# SN32F400 register map
Vendor: SONiX Technology Co., Ltd.; Series: SN32F400; File version: 1.1
CPU: CM0 r0p0, little endian, no MPU, no FPU, 2 interrupt priority bits
Registers are 32-bit, read-write, reset 0x0 unless marked. A register's access mark holds for its fields unless they carry their own. Offsets are from the block's base; [hi:lo] are bit positions.

## SN_GPIO1 — General Purpose I/O
Base 0x40046000
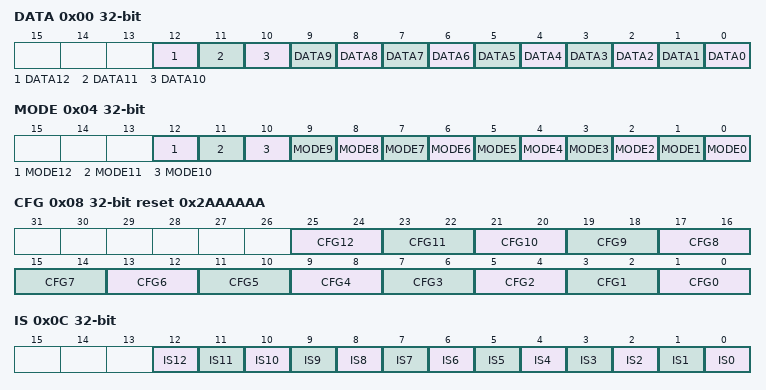
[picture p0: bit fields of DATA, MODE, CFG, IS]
0x00 DATA — Offset:0x00 GPIO Port n Data register
  [12] DATA12 — Data of Pn.12
    0=Low (Pn.12 is 0); 1=High (Pn.12 is 1)
  [11] DATA11 — Data of Pn.11
    0=Low (Pn.11 is 0); 1=High (Pn.11 is 1)
  [10] DATA10 — Data of Pn.10
    0=Low (Pn.10 is 0); 1=High (Pn.10 is 1)
  [9] DATA9 — Data of Pn.9
    0=Low (Pn.9 is 0); 1=High (Pn.9 is 1)
  [8] DATA8 — Data of Pn.8
    0=Low (Pn.8 is 0); 1=High (Pn.8 is 1)
  [7] DATA7 — Data of Pn.7
    0=Low (Pn.7 is 0); 1=High (Pn.7 is 1)
  [6] DATA6 — Data of Pn.6
    0=Low (Pn.6 is 0); 1=High (Pn.6 is 1)
  [5] DATA5 — Data of Pn.5
    0=Low (Pn.5 is 0); 1=High (Pn.5 is 1)
  [4] DATA4 — Data of Pn.4
    0=Low (Pn.4 is 0); 1=High (Pn.4 is 1)
  [3] DATA3 — Data of Pn.3
    0=Low (Pn.3 is 0); 1=High (Pn.3 is 1)
  [2] DATA2 — Data of Pn.2
    0=Low (Pn.2 is 0); 1=High (Pn.2 is 1)
  [1] DATA1 — Data of Pn.1
    0=Low (Pn.1 is 0); 1=High (Pn.1 is 1)
  [0] DATA0 — Data of Pn.0
    0=Low (Pn.0 is 0); 1=High (Pn.0 is 1)
0x04 MODE — Offset:0x04 GPIO Port n Mode register
  [12] MODE12 — Mode of Pn.12
    0=I (Pn.12 is Input pin); 1=O (Pn.12 is Output pin)
  [11] MODE11 — Mode of Pn.11
    0=I (Pn.11 is Input pin); 1=O (Pn.11 is Output pin)
  [10] MODE10 — Mode of Pn.10
    0=I (Pn.10 is Input pin); 1=O (Pn.10 is Output pin)
  [9] MODE9 — Mode of Pn.9
    0=I (Pn.9 is Input pin); 1=O (Pn.9 is Output pin)
  [8] MODE8 — Mode of Pn.8
    0=I (Pn.8 is Input pin); 1=O (Pn.8 is Output pin)
  [7] MODE7 — Mode of Pn.7
    0=I (Pn.7 is Input pin); 1=O (Pn.7 is Output pin)
  [6] MODE6 — Mode of Pn.6
    0=I (Pn.6 is Input pin); 1=O (Pn.6 is Output pin)
  [5] MODE5 — Mode of Pn.5
    0=I (Pn.5 is Input pin); 1=O (Pn.5 is Output pin)
  [4] MODE4 — Mode of Pn.4
    0=I (Pn.4 is Input pin); 1=O (Pn.4 is Output pin)
  [3] MODE3 — Mode of Pn.3
    0=I (Pn.3 is Input pin); 1=O (Pn.3 is Output pin)
  [2] MODE2 — Mode of Pn.2
    0=I (Pn.2 is Input pin); 1=O (Pn.2 is Output pin)
  [1] MODE1 — Mode of Pn.1
    0=I (Pn.1 is Input pin); 1=O (Pn.1 is Output pin)
  [0] MODE0 — Mode of Pn.0
    0=I (Pn.0 is Input pin); 1=O (Pn.0 is Output pin)
0x08 CFG reset 0x2AAAAAA — Offset:0x08 GPIO Port n Configuration register
  [all] fields
    0=00b (Enable pull-up resistor); 1=01b (Enable pull-down resistor); 2=10b (Inactive (schmitt trigger enabled)); 3=11b (Inactive (schmitt trigger disabled))
  [25:24] CFG12 — Configuration of Pn.12
  [23:22] CFG11 — Configuration of Pn.11
  [21:20] CFG10 — Configuration of Pn.10
  [19:18] CFG9 — Configuration of Pn.9
  [17:16] CFG8 — Configuration of Pn.8
  [15:14] CFG7 — Configuration of Pn.7
  [13:12] CFG6 — Configuration of Pn.6
  [11:10] CFG5 — Configuration of Pn.5
  [9:8] CFG4 — Configuration of Pn.4
  [7:6] CFG3 — Configuration of Pn.3
  [5:4] CFG2 — Configuration of Pn.2
  [3:2] CFG1 — Configuration of Pn.1
  [1:0] CFG0 — Configuration of Pn.0
0x0C IS — Offset:0x0C GPIO Port n Interrupt Sense register
  [12] IS12 — Interrupt on Pn.12 is event or edge sensitive
    0=Edge (Interrupt on Pn.12 is edge sensitive); 1=Event (Interrupt on Pn.12 is event sensitive)
  [11] IS11 — Interrupt on Pn.11 is event or edge sensitive
    0=Edge (Interrupt on Pn.11 is edge sensitive); 1=Event (Interrupt on Pn.11 is event sensitive)
  [10] IS10 — Interrupt on Pn.10 is event or edge sensitive
    0=Edge (Interrupt on Pn.10 is edge sensitive); 1=Event (Interrupt on Pn.10 is event sensitive)
  [9] IS9 — Interrupt on Pn.9 is event or edge sensitive
    0=Edge (Interrupt on Pn.9 is edge sensitive); 1=Event (Interrupt on Pn.9 is event sensitive)
  [8] IS8 — Interrupt on Pn.8 is event or edge sensitive
    0=Edge (Interrupt on Pn.8 is edge sensitive); 1=Event (Interrupt on Pn.8 is event sensitive)
  [7] IS7 — Interrupt on Pn.7 is event or edge sensitive
    0=Edge (Interrupt on Pn.7 is edge sensitive); 1=Event (Interrupt on Pn.7 is event sensitive)
  [6] IS6 — Interrupt on Pn.6 is event or edge sensitive
    0=Edge (Interrupt on Pn.6 is edge sensitive); 1=Event (Interrupt on Pn.6 is event sensitive)
  [5] IS5 — Interrupt on Pn.5 is event or edge sensitive
    0=Edge (Interrupt on Pn.5 is edge sensitive); 1=Event (Interrupt on Pn.5 is event sensitive)
  [4] IS4 — Interrupt on Pn.4 is event or edge sensitive
    0=Edge (Interrupt on Pn.4 is edge sensitive); 1=Event (Interrupt on Pn.4 is event sensitive)
  [3] IS3 — Interrupt on Pn.3 is event or edge sensitive
    0=Edge (Interrupt on Pn.3 is edge sensitive); 1=Event (Interrupt on Pn.3 is event sensitive)
  [2] IS2 — Interrupt on Pn.2 is event or edge sensitive
    0=Edge (Interrupt on Pn.2 is edge sensitive); 1=Event (Interrupt on Pn.2 is event sensitive)
  [1] IS1 — Interrupt on Pn.1 is event or edge sensitive
    0=Edge (Interrupt on Pn.1 is edge sensitive); 1=Event (Interrupt on Pn.1 is event sensitive)
  [0] IS0 — Interrupt on Pn.0 is event or edge sensitive
    0=Edge (Interrupt on Pn.0 is edge sensitive); 1=Event (Interrupt on Pn.0 is event sensitive)
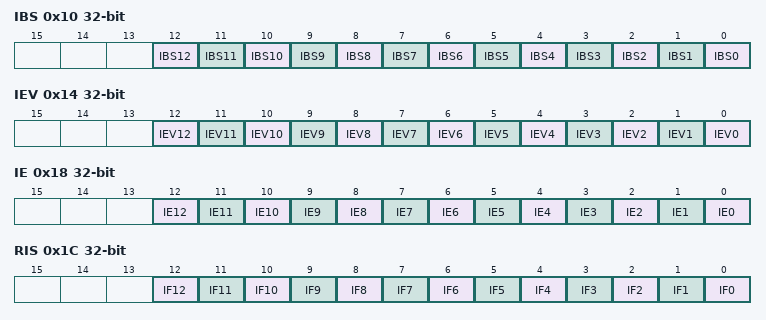
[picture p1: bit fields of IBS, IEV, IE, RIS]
0x10 IBS — Offset:0x10 GPIO Port n Interrupt Both-edge Sense register
  [12] IBS12 — Interrupt on Pn.12 is triggered ob both edges
    0=IEV (Interrupt on Pn.12 is controlled by GPIOn_IEV register); 1=Both edges on Pn.12 trigger an interrupt
  [11] IBS11 — Interrupt on Pn.11 is triggered ob both edges
    0=IEV (Interrupt on Pn.11 is controlled by GPIOn_IEV register); 1=Both edges on Pn.11 trigger an interrupt
  [10] IBS10 — Interrupt on Pn.10 is triggered ob both edges
    0=IEV (Interrupt on Pn.10 is controlled by GPIOn_IEV register); 1=Both edges on Pn.10 trigger an interrupt
  [9] IBS9 — Interrupt on Pn.9 is triggered ob both edges
    0=IEV (Interrupt on Pn.9 is controlled by GPIOn_IEV register); 1=Both edges on Pn.9 trigger an interrupt
  [8] IBS8 — Interrupt on Pn.8 is triggered ob both edges
    0=IEV (Interrupt on Pn.8 is controlled by GPIOn_IEV register); 1=Both edges on Pn.8 trigger an interrupt
  [7] IBS7 — Interrupt on Pn.7 is triggered ob both edges
    0=IEV (Interrupt on Pn.7 is controlled by GPIOn_IEV register); 1=Both edges on Pn.7 trigger an interrupt
  [6] IBS6 — Interrupt on Pn.6 is triggered ob both edges
    0=IEV (Interrupt on Pn.6 is controlled by GPIOn_IEV register); 1=Both edges on Pn.6 trigger an interrupt
  [5] IBS5 — Interrupt on Pn.5 is triggered ob both edges
    0=IEV (Interrupt on Pn.5 is controlled by GPIOn_IEV register); 1=Both edges on Pn.5 trigger an interrupt
  [4] IBS4 — Interrupt on Pn.4 is triggered ob both edges
    0=IEV (Interrupt on Pn.4 is controlled by GPIOn_IEV register); 1=Both edges on Pn.4 trigger an interrupt
  [3] IBS3 — Interrupt on Pn.3 is triggered ob both edges
    0=IEV (Interrupt on Pn.3 is controlled by GPIOn_IEV register); 1=Both edges on Pn.3 trigger an interrupt
  [2] IBS2 — Interrupt on Pn.2 is triggered ob both edges
    0=IEV (Interrupt on Pn.2 is controlled by GPIOn_IEV register); 1=Both edges on Pn.2 trigger an interrupt
  [1] IBS1 — Interrupt on Pn.1 is triggered ob both edges
    0=IEV (Interrupt on Pn.1 is controlled by GPIOn_IEV register); 1=Both edges on Pn.1 trigger an interrupt
  [0] IBS0 — Interrupt on Pn.0 is triggered ob both edges
    0=IEV (Interrupt on Pn.0 is controlled by GPIOn_IEV register); 1=Both edges on Pn.0 trigger an interrupt
0x14 IEV — Offset:0x14 GPIO Port n Interrupt Event register
  [12] IEV12 — Interrupt trigged event on Pn.12
    0=Rising/High (Rising edge or High level on Pn.12 triggers an interrupt); 1=Falling/Low (Falling edge or Low level on Pn.12 triggers an interrupt)
  [11] IEV11 — Interrupt trigged event on Pn.11
    0=Rising/High (Rising edge or High level on Pn.11 triggers an interrupt); 1=Falling/Low (Falling edge or Low level on Pn.11 triggers an interrupt)
  [10] IEV10 — Interrupt trigged event on Pn.10
    0=Rising/High (Rising edge or High level on Pn.10 triggers an interrupt); 1=Falling/Low (Falling edge or Low level on Pn.10 triggers an interrupt)
  [9] IEV9 — Interrupt trigged event on Pn.9
    0=Rising/High (Rising edge or High level on Pn.9 triggers an interrupt); 1=Falling/Low (Falling edge or Low level on Pn.9 triggers an interrupt)
  [8] IEV8 — Interrupt trigged event on Pn.8
    0=Rising/High (Rising edge or High level on Pn.8 triggers an interrupt); 1=Falling/Low (Falling edge or Low level on Pn.8 triggers an interrupt)
  [7] IEV7 — Interrupt trigged event on Pn.7
    0=Rising/High (Rising edge or High level on Pn.7 triggers an interrupt); 1=Falling/Low (Falling edge or Low level on Pn.7 triggers an interrupt)
  [6] IEV6 — Interrupt trigged event on Pn.6
    0=Rising/High (Rising edge or High level on Pn.6 triggers an interrupt); 1=Falling/Low (Falling edge or Low level on Pn.6 triggers an interrupt)
  [5] IEV5 — Interrupt trigged event on Pn.5
    0=Rising/High (Rising edge or High level on Pn.5 triggers an interrupt); 1=Falling/Low (Falling edge or Low level on Pn.5 triggers an interrupt)
  [4] IEV4 — Interrupt trigged event on Pn.4
    0=Rising/High (Rising edge or High level on Pn.4 triggers an interrupt); 1=Falling/Low (Falling edge or Low level on Pn.4 triggers an interrupt)
  [3] IEV3 — Interrupt trigged event on Pn.3
    0=Rising/High (Rising edge or High level on Pn.3 triggers an interrupt); 1=Falling/Low (Falling edge or Low level on Pn.3 triggers an interrupt)
  [2] IEV2 — Interrupt trigged event on Pn.2
    0=Rising/High (Rising edge or High level on Pn.2 triggers an interrupt); 1=Falling/Low (Falling edge or Low level on Pn.2 triggers an interrupt)
  [1] IEV1 — Interrupt trigged event on Pn.1
    0=Rising/High (Rising edge or High level on Pn.1 triggers an interrupt); 1=Falling/Low (Falling edge or Low level on Pn.1 triggers an interrupt)
  [0] IEV0 — Interrupt trigged event on Pn.0
    0=Rising/High (Rising edge or High level on Pn.0 triggers an interrupt); 1=Falling/Low (Falling edge or Low level on Pn.0 triggers an interrupt)
0x18 IE — Offset:0x18 GPIO Port n Interrupt Enable register
  [12] IE12 — Interrupt on Pn.12 enable
    0=Disable interrupt on Pn.12; 1=Enable interrupt on Pn.12
  [11] IE11 — Interrupt on Pn.11 enable
    0=Disable interrupt on Pn.11; 1=Enable interrupt on Pn.11
  [10] IE10 — Interrupt on Pn.10 enable
    0=Disable interrupt on Pn.10; 1=Enable interrupt on Pn.10
  [9] IE9 — Interrupt on Pn.9 enable
    0=Disable interrupt on Pn.9; 1=Enable interrupt on Pn.9
  [8] IE8 — Interrupt on Pn.8 enable
    0=Disable interrupt on Pn.8; 1=Enable interrupt on Pn.8
  [7] IE7 — Interrupt on Pn.7 enable
    0=Disable interrupt on Pn.7; 1=Enable interrupt on Pn.7
  [6] IE6 — Interrupt on Pn.6 enable
    0=Disable interrupt on Pn.6; 1=Enable interrupt on Pn.6
  [5] IE5 — Interrupt on Pn.5 enable
    0=Disable interrupt on Pn.5; 1=Enable interrupt on Pn.5
  [4] IE4 — Interrupt on Pn.4 enable
    0=Disable interrupt on Pn.4; 1=Enable interrupt on Pn.4
  [3] IE3 — Interrupt on Pn.3 enable
    0=Disable interrupt on Pn.3; 1=Enable interrupt on Pn.3
  [2] IE2 — Interrupt on Pn.2 enable
    0=Disable interrupt on Pn.2; 1=Enable interrupt on Pn.2
  [1] IE1 — Interrupt on Pn.1 enable
    0=Disable interrupt on Pn.1; 1=Enable interrupt on Pn.1
  [0] IE0 — Interrupt on Pn.0 enable
    0=Disable interrupt on Pn.0; 1=Enable interrupt on Pn.0
0x1C RIS ro — Offset:0x1C GPIO Port n Raw Interrupt Status register
  [12] IF12 — Pn.12 raw interrupt flag
    0=None (No interrupt on Pn.12); 1=Met interrupt requirements (Interrupt requirements met on Pn.12)
  [11] IF11 — Pn.11 raw interrupt flag
    0=None (No interrupt on Pn.11); 1=Met interrupt requirements (Interrupt requirements met on Pn.11)
  [10] IF10 — Pn.10 raw interrupt flag
    0=None (No interrupt on Pn.10); 1=Met interrupt requirements (Interrupt requirements met on Pn.10)
  [9] IF9 — Pn.9 raw interrupt flag
    0=None (No interrupt on Pn.9); 1=Met interrupt requirements (Interrupt requirements met on Pn.9)
  [8] IF8 — Pn.8 raw interrupt flag
    0=None (No interrupt on Pn.8); 1=Met interrupt requirements (Interrupt requirements met on Pn.8)
  [7] IF7 — Pn.7 raw interrupt flag
    0=None (No interrupt on Pn.7); 1=Met interrupt requirements (Interrupt requirements met on Pn.7)
  [6] IF6 — Pn.6 raw interrupt flag
    0=None (No interrupt on Pn.6); 1=Met interrupt requirements (Interrupt requirements met on Pn.6)
  [5] IF5 — Pn.5 raw interrupt flag
    0=None (No interrupt on Pn.5); 1=Met interrupt requirements (Interrupt requirements met on Pn.5)
  [4] IF4 — Pn.4 raw interrupt flag
    0=None (No interrupt on Pn.4); 1=Met interrupt requirements (Interrupt requirements met on Pn.4)
  [3] IF3 — Pn.3 raw interrupt flag
    0=None (No interrupt on Pn.3); 1=Met interrupt requirements (Interrupt requirements met on Pn.3)
  [2] IF2 — Pn.2 raw interrupt flag
    0=None (No interrupt on Pn.2); 1=Met interrupt requirements (Interrupt requirements met on Pn.2)
  [1] IF1 — Pn.1 raw interrupt flag
    0=None (No interrupt on Pn.1); 1=Met interrupt requirements (Interrupt requirements met on Pn.1)
  [0] IF0 — Pn.0 raw interrupt flag
    0=None (No interrupt on Pn.0); 1=Met interrupt requirements (Interrupt requirements met on Pn.0)
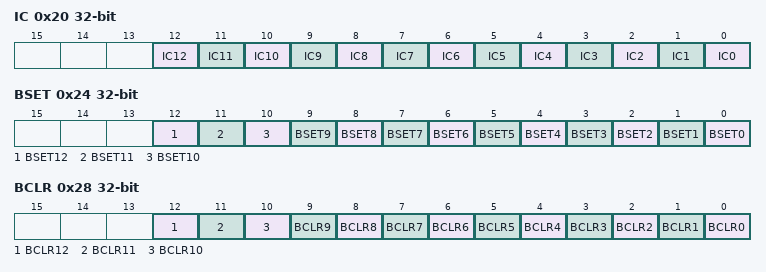
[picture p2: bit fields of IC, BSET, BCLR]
0x20 IC wo — Offset:0x20 GPIO Port n Interrupt Clear register
  [12] IC12 — Pn.12 interrupt flag clear
    0=None (No effect); 1=Clear interrupt flag on Pn.12
  [11] IC11 — Pn.11 interrupt flag clear
    0=None (No effect); 1=Clear interrupt flag on Pn.11
  [10] IC10 — Pn.10 interrupt flag clear
    0=None (No effect); 1=Clear interrupt flag on Pn.10
  [9] IC9 — Pn.9 interrupt flag clear
    0=None (No effect); 1=Clear interrupt flag on Pn.9
  [8] IC8 — Pn.8 interrupt flag clear
    0=None (No effect); 1=Clear interrupt flag on Pn.8
  [7] IC7 — Pn.7 interrupt flag clear
    0=None (No effect); 1=Clear interrupt flag on Pn.7
  [6] IC6 — Pn.6 interrupt flag clear
    0=None (No effect); 1=Clear interrupt flag on Pn.6
  [5] IC5 — Pn.5 interrupt flag clear
    0=None (No effect); 1=Clear interrupt flag on Pn.5
  [4] IC4 — Pn.4 interrupt flag clear
    0=None (No effect); 1=Clear interrupt flag on Pn.4
  [3] IC3 — Pn.3 interrupt flag clear
    0=None (No effect); 1=Clear interrupt flag on Pn.3
  [2] IC2 — Pn.2 interrupt flag clear
    0=None (No effect); 1=Clear interrupt flag on Pn.2
  [1] IC1 — Pn.1 interrupt flag clear
    0=None (No effect); 1=Clear interrupt flag on Pn.1
  [0] IC0 — Pn.0 interrupt flag clear
    0=None (No effect); 1=Clear interrupt flag on Pn.0
0x24 BSET wo — Offset:0x24 GPIO Port n Bits Set Operation register
  [12] BSET12 — Set Pn.12
    0=None (No effect); 1=Set (Set Pn.12 to 1)
  [11] BSET11 — Set Pn.11
    0=None (No effect); 1=Set (Set Pn.11 to 1)
  [10] BSET10 — Set Pn.10
    0=None (No effect); 1=Set (Set Pn.10 to 1)
  [9] BSET9 — Set Pn.9
    0=None (No effect); 1=Set (Set Pn.9 to 1)
  [8] BSET8 — Set Pn.8
    0=None (No effect); 1=Set (Set Pn.8 to 1)
  [7] BSET7 — Set Pn.7
    0=None (No effect); 1=Set (Set Pn.7 to 1)
  [6] BSET6 — Set Pn.6
    0=None (No effect); 1=Set (Set Pn.6 to 1)
  [5] BSET5 — Set Pn.5
    0=None (No effect); 1=Set (Set Pn.5 to 1)
  [4] BSET4 — Set Pn.4
    0=None (No effect); 1=Set (Set Pn.4 to 1)
  [3] BSET3 — Set Pn.3
    0=None (No effect); 1=Set (Set Pn.3 to 1)
  [2] BSET2 — Set Pn.2
    0=None (No effect); 1=Set (Set Pn.2 to 1)
  [1] BSET1 — Set Pn.1
    0=None (No effect); 1=Set (Set Pn.1 to 1)
  [0] BSET0 — Set Pn.0
    0=None (No effect); 1=Set (Set Pn.0 to 1)
0x28 BCLR wo — Offset:0x28 GPIO Port n Bits Clear Operation register
  [12] BCLR12 — Clear Pn.12
    0=None (No effect); 1=Clear Pn.12
  [11] BCLR11 — Clear Pn.11
    0=None (No effect); 1=Clear Pn.11
  [10] BCLR10 — Clear Pn.10
    0=None (No effect); 1=Clear Pn.10
  [9] BCLR9 — Clear Pn.9
    0=None (No effect); 1=Clear Pn.9
  [8] BCLR8 — Clear Pn.8
    0=None (No effect); 1=Clear Pn.8
  [7] BCLR7 — Clear Pn.7
    0=None (No effect); 1=Clear Pn.7
  [6] BCLR6 — Clear Pn.6
    0=None (No effect); 1=Clear Pn.6
  [5] BCLR5 — Clear Pn.5
    0=None (No effect); 1=Clear Pn.5
  [4] BCLR4 — Clear Pn.4
    0=None (No effect); 1=Clear Pn.4
  [3] BCLR3 — Clear Pn.3
    0=None (No effect); 1=Clear Pn.3
  [2] BCLR2 — Clear Pn.2
    0=None (No effect); 1=Clear Pn.2
  [1] BCLR1 — Clear Pn.1
    0=None (No effect); 1=Clear Pn.1
  [0] BCLR0 — Clear Pn.0
    0=None (No effect); 1=Clear Pn.0
